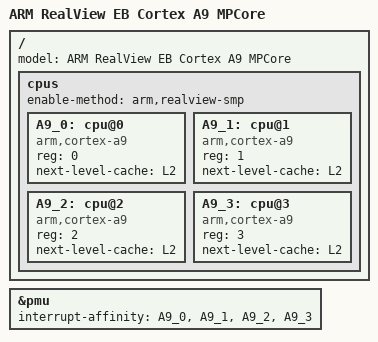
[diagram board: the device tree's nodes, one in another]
/dts-v1/;
#include "arm-realview-eb-mp.dtsi"
/ {
	model = "ARM RealView EB Cortex A9 MPCore";
	cpus {
		#address-cells = <1>;
		#size-cells = <0>;
		enable-method = "arm,realview-smp";
		A9_0: cpu@0 {
			device_type = "cpu";
			compatible = "arm,cortex-a9";
			reg = <0>;
			next-level-cache = <&L2>;
		};
		A9_1: cpu@1 {
			device_type = "cpu";
			compatible = "arm,cortex-a9";
			reg = <1>;
			next-level-cache = <&L2>;
		};
		A9_2: cpu@2 {
			device_type = "cpu";
			compatible = "arm,cortex-a9";
			reg = <2>;
			next-level-cache = <&L2>;
		};
		A9_3: cpu@3 {
			device_type = "cpu";
			compatible = "arm,cortex-a9";
			reg = <3>;
			next-level-cache = <&L2>;
		};
	};
};
&pmu {
	interrupt-affinity = <&A9_0>, <&A9_1>, <&A9_2>, <&A9_3>;
};
